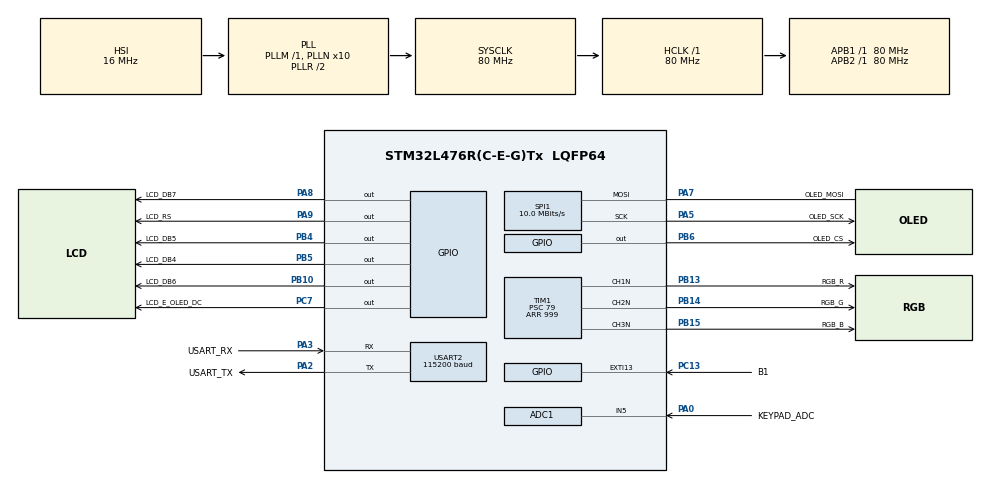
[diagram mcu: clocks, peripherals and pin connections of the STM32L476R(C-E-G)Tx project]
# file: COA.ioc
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ADC1.Channel-0\#ChannelRegularConversion=ADC_CHANNEL_5
ADC1.ClockPrescaler=ADC_CLOCK_ASYNC_DIV4
ADC1.NbrOfConversionFlag=1
ADC1.OffsetNumber-0\#ChannelRegularConversion=ADC_OFFSET_NONE
ADC1.Overrun=ADC_OVR_DATA_OVERWRITTEN
ADC1.Rank-0\#ChannelRegularConversion=1
ADC1.SamplingTime-0\#ChannelRegularConversion=ADC_SAMPLETIME_47CYCLES_5
ADC1.master=1
Mcu.Family=STM32L4
Mcu.Name=STM32L476R(C-E-G)Tx
Mcu.Package=LQFP64
NUCLEO-L476RG.BUTTON=1
NUCLEO-L476RG.LD2=false
NVIC.EXTI15_10_IRQn=true\:0\:0\:false\:false\:true\:false\:true\:true
NVIC.PriorityGroup=NVIC_PRIORITYGROUP_4
NVIC.TIM6_DAC_IRQn=true\:1\:0\:false\:false\:true\:true\:true\:true
PA0.GPIO_Label=KEYPAD_ADC
PA0.Mode=IN5-Single-Ended
PA0.Signal=ADC1_IN5
PA13\ (JTMS-SWDIO).GPIO_Label=TMS
PA13\ (JTMS-SWDIO).Signal=SYS_JTMS-SWDIO
PA14\ (JTCK-SWCLK).GPIO_Label=TCK
PA14\ (JTCK-SWCLK).Signal=SYS_JTCK-SWCLK
PA2.GPIO_Label=USART_TX
PA2.GPIO_Mode=GPIO_MODE_AF_PP
PA2.GPIO_PuPd=GPIO_NOPULL
PA2.GPIO_Speed=GPIO_SPEED_FREQ_VERY_HIGH
PA2.Mode=Asynchronous
PA2.Signal=USART2_TX
PA3.GPIO_Label=USART_RX
PA3.GPIO_Mode=GPIO_MODE_AF_PP
PA3.GPIO_PuPd=GPIO_NOPULL
PA3.GPIO_Speed=GPIO_SPEED_FREQ_VERY_HIGH
PA3.Mode=Asynchronous
PA3.Signal=USART2_RX
PA5.GPIO_Label=OLED_SCK
PA5.Mode=Simplex_Bidirectional_Master
PA5.Signal=SPI1_SCK
PA7.GPIO_Label=OLED_MOSI
PA7.Mode=Simplex_Bidirectional_Master
PA7.Signal=SPI1_MOSI
PA8.GPIO_Label=LCD_DB7
PA8.Signal=GPIO_Output
PA9.GPIO_Label=LCD_RS
PA9.Signal=GPIO_Output
PB10.GPIO_Label=LCD_DB6
PB10.Signal=GPIO_Output
PB13.GPIO_Label=RGB_R
PB13.Signal=S_TIM1_CH1N
PB14.GPIO_Label=RGB_G
PB14.Signal=S_TIM1_CH2N
PB15.GPIO_Label=RGB_B
PB15.Signal=S_TIM1_CH3N
PB3\ (JTDO-TRACESWO).GPIO_Label=SWO
PB3\ (JTDO-TRACESWO).Signal=SYS_JTDO-SWO
PB4\ (NJTRST).GPIO_Label=LCD_DB5
PB4\ (NJTRST).Signal=GPIO_Output
PB5.GPIO_Label=LCD_DB4
PB5.Signal=GPIO_Output
PB6.GPIO_Label=OLED_CS
PB6.PinState=GPIO_PIN_SET
PB6.Signal=GPIO_Output
PC13.GPIO_Label=B1
PC13.Signal=GPXTI13
PC14-OSC32_IN\ (PC14).Signal=RCC_OSC32_IN
PC15-OSC32_OUT\ (PC15).Signal=RCC_OSC32_OUT
PC7.GPIO_Label=LCD_E_OLED_DC
PC7.Signal=GPIO_Output
PH0-OSC_IN\ (PH0).Signal=RCC_OSC_IN
PH1-OSC_OUT\ (PH1).Signal=RCC_OSC_OUT
ProjectManager.HeapSize=0x200
ProjectManager.StackSize=0x400
ProjectManager.TargetToolchain=STM32CubeIDE
RCC.ADCFreq_Value=64000000
RCC.AHBFreq_Value=80000000
RCC.APB1Freq_Value=80000000
RCC.APB1TimFreq_Value=80000000
RCC.APB2Freq_Value=80000000
RCC.APB2TimFreq_Value=80000000
RCC.CortexFreq_Value=80000000
RCC.HCLKFreq_Value=80000000
RCC.HSE_VALUE=8000000
RCC.HSI_VALUE=16000000
RCC.LSE_VALUE=32768
RCC.MSI_VALUE=4000000
RCC.PLLN=10
RCC.PLLSourceVirtual=RCC_PLLSOURCE_HSI
RCC.PREFETCH_ENABLE=1
RCC.SYSCLKFreq_VALUE=80000000
RCC.SYSCLKSource=RCC_SYSCLKSOURCE_PLLCLK
RCC.USBFreq_Value=64000000
RCC.VCOOutputFreq_Value=160000000
SH.ADCx_IN5.0=ADC1_IN5,IN5-Single-Ended
SH.S_TIM1_CH1N.0=TIM1_CH1N,PWM Generation1 CH1N
SH.S_TIM1_CH2N.0=TIM1_CH2N,PWM Generation2 CH2N
SH.S_TIM1_CH3N.0=TIM1_CH3N,PWM Generation3 CH3N
SPI1.BaudRatePrescaler=SPI_BAUDRATEPRESCALER_8
SPI1.CalculateBaudRate=10.0 MBits/s
SPI1.DataSize=SPI_DATASIZE_8BIT
SPI1.Direction=SPI_DIRECTION_2LINES
SPI1.Mode=SPI_MODE_MASTER
SPI1.NSSPMode=SPI_NSS_PULSE_DISABLE
SPI1.VirtualType=VM_MASTER
TIM1.Channel-PWM\ Generation1\ CH1N=TIM_CHANNEL_1
TIM1.Channel-PWM\ Generation2\ CH2N=TIM_CHANNEL_2
TIM1.Channel-PWM\ Generation3\ CH3N=TIM_CHANNEL_3
TIM1.Period=999
TIM1.Prescaler=79
TIM6.Period=999
TIM6.Prescaler=79
USART2.BaudRate=115200
USART2.VirtualMode-Asynchronous=VM_ASYNC
VP_NUCLEO-L476RG_VS_BSP_COMMON.Mode=COMMON
VP_TIM1_VS_ClockSourceINT.Mode=Internal
VP_TIM6_VS_ClockSourceINT.Mode=Enable_Timer
board=NUCLEO-L476RG

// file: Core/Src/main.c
/* USER CODE BEGIN Header */
/**
  ******************************************************************************
  * @file           : main.c
  * @brief          : Main program body
  ******************************************************************************
  * @attention
  *
  * Copyright (c) 2026 STMicroelectronics.
  * All rights reserved.
  *
  * This software is licensed under terms that can be found in the LICENSE file
  * in the root directory of this software component.
  * If no LICENSE file comes with this software, it is provided AS-IS.
  *
  ******************************************************************************
  */
/* USER CODE END Header */
#include "main.h"

/* USER CODE BEGIN Includes */
#include "app.h"
#include <stdio.h>
/* USER CODE END Includes */

ADC_HandleTypeDef hadc1;

SPI_HandleTypeDef hspi1;

TIM_HandleTypeDef htim1;
TIM_HandleTypeDef htim6;

UART_HandleTypeDef huart2;

void SystemClock_Config(void);
static void MX_GPIO_Init(void);
static void MX_ADC1_Init(void);
static void MX_SPI1_Init(void);
static void MX_TIM1_Init(void);
static void MX_TIM6_Init(void);
static void MX_USART2_UART_Init(void);

int main(void)
{

  /* MCU Configuration--------------------------------------------------------*/

  /* Reset of all peripherals, Initializes the Flash interface and the Systick. */
  HAL_Init();

  /* Configure the system clock */
  SystemClock_Config();

  /* Initialize all configured peripherals */
  MX_GPIO_Init();
  MX_ADC1_Init();
  MX_SPI1_Init();
  MX_TIM1_Init();
  MX_TIM6_Init();
  MX_USART2_UART_Init();
  /* USER CODE BEGIN 2 */
  App_Init();      /* game init (also starts the TIM6 game tick) */
  /* USER CODE END 2 */

  /* Initialize USER push-button, will be used to trigger an interrupt each time it's pressed.*/
  BSP_PB_Init(BUTTON_USER, BUTTON_MODE_EXTI);

  /* Infinite loop */
  while (1)
  {

    /* USER CODE BEGIN 3 */
    App_Loop();
  }
  /* USER CODE END 3 */
}

void SystemClock_Config(void)
{
  RCC_OscInitTypeDef RCC_OscInitStruct = {0};
  RCC_ClkInitTypeDef RCC_ClkInitStruct = {0};

  /** Configure the main internal regulator output voltage
  */
  if (HAL_PWREx_ControlVoltageScaling(PWR_REGULATOR_VOLTAGE_SCALE1) != HAL_OK)
  {
    Error_Handler();
  }

  /** Initializes the RCC Oscillators according to the specified parameters
  * in the RCC_OscInitTypeDef structure.
  */
  RCC_OscInitStruct.OscillatorType = RCC_OSCILLATORTYPE_HSI;
  RCC_OscInitStruct.HSIState = RCC_HSI_ON;
  RCC_OscInitStruct.HSICalibrationValue = RCC_HSICALIBRATION_DEFAULT;
  RCC_OscInitStruct.PLL.PLLState = RCC_PLL_ON;
  RCC_OscInitStruct.PLL.PLLSource = RCC_PLLSOURCE_HSI;
  RCC_OscInitStruct.PLL.PLLM = 1;
  RCC_OscInitStruct.PLL.PLLN = 10;
  RCC_OscInitStruct.PLL.PLLP = RCC_PLLP_DIV7;
  RCC_OscInitStruct.PLL.PLLQ = RCC_PLLQ_DIV2;
  RCC_OscInitStruct.PLL.PLLR = RCC_PLLR_DIV2;
  if (HAL_RCC_OscConfig(&RCC_OscInitStruct) != HAL_OK)
  {
    Error_Handler();
  }

  /** Initializes the CPU, AHB and APB buses clocks
  */
  RCC_ClkInitStruct.ClockType = RCC_CLOCKTYPE_HCLK|RCC_CLOCKTYPE_SYSCLK
                              |RCC_CLOCKTYPE_PCLK1|RCC_CLOCKTYPE_PCLK2;
  RCC_ClkInitStruct.SYSCLKSource = RCC_SYSCLKSOURCE_PLLCLK;
  RCC_ClkInitStruct.AHBCLKDivider = RCC_SYSCLK_DIV1;
  RCC_ClkInitStruct.APB1CLKDivider = RCC_HCLK_DIV1;
  RCC_ClkInitStruct.APB2CLKDivider = RCC_HCLK_DIV1;

  if (HAL_RCC_ClockConfig(&RCC_ClkInitStruct, FLASH_LATENCY_4) != HAL_OK)
  {
    Error_Handler();
  }
}

static void MX_ADC1_Init(void)
{

  ADC_MultiModeTypeDef multimode = {0};
  ADC_ChannelConfTypeDef sConfig = {0};

  /** Common config
  */
  hadc1.Instance = ADC1;
  hadc1.Init.ClockPrescaler = ADC_CLOCK_ASYNC_DIV4;
  hadc1.Init.Resolution = ADC_RESOLUTION_12B;
  hadc1.Init.DataAlign = ADC_DATAALIGN_RIGHT;
  hadc1.Init.ScanConvMode = ADC_SCAN_DISABLE;
  hadc1.Init.EOCSelection = ADC_EOC_SINGLE_CONV;
  hadc1.Init.LowPowerAutoWait = DISABLE;
  hadc1.Init.ContinuousConvMode = DISABLE;
  hadc1.Init.NbrOfConversion = 1;
  hadc1.Init.DiscontinuousConvMode = DISABLE;
  hadc1.Init.ExternalTrigConv = ADC_SOFTWARE_START;
  hadc1.Init.ExternalTrigConvEdge = ADC_EXTERNALTRIGCONVEDGE_NONE;
  hadc1.Init.DMAContinuousRequests = DISABLE;
  hadc1.Init.Overrun = ADC_OVR_DATA_OVERWRITTEN;
  hadc1.Init.OversamplingMode = DISABLE;
  if (HAL_ADC_Init(&hadc1) != HAL_OK)
  {
    Error_Handler();
  }

  /** Configure the ADC multi-mode
  */
  multimode.Mode = ADC_MODE_INDEPENDENT;
  if (HAL_ADCEx_MultiModeConfigChannel(&hadc1, &multimode) != HAL_OK)
  {
    Error_Handler();
  }

  /** Configure Regular Channel
  */
  sConfig.Channel = ADC_CHANNEL_5;
  sConfig.Rank = ADC_REGULAR_RANK_1;
  sConfig.SamplingTime = ADC_SAMPLETIME_47CYCLES_5;
  sConfig.SingleDiff = ADC_SINGLE_ENDED;
  sConfig.OffsetNumber = ADC_OFFSET_NONE;
  sConfig.Offset = 0;
  if (HAL_ADC_ConfigChannel(&hadc1, &sConfig) != HAL_OK)
  {
    Error_Handler();
  }

}

static void MX_SPI1_Init(void)
{

  /* SPI1 parameter configuration*/
  hspi1.Instance = SPI1;
  hspi1.Init.Mode = SPI_MODE_MASTER;
  hspi1.Init.Direction = SPI_DIRECTION_2LINES;
  hspi1.Init.DataSize = SPI_DATASIZE_8BIT;
  hspi1.Init.CLKPolarity = SPI_POLARITY_LOW;
  hspi1.Init.CLKPhase = SPI_PHASE_1EDGE;
  hspi1.Init.NSS = SPI_NSS_SOFT;
  hspi1.Init.BaudRatePrescaler = SPI_BAUDRATEPRESCALER_8;
  hspi1.Init.FirstBit = SPI_FIRSTBIT_MSB;
  hspi1.Init.TIMode = SPI_TIMODE_DISABLE;
  hspi1.Init.CRCCalculation = SPI_CRCCALCULATION_DISABLE;
  hspi1.Init.CRCPolynomial = 7;
  hspi1.Init.CRCLength = SPI_CRC_LENGTH_DATASIZE;
  hspi1.Init.NSSPMode = SPI_NSS_PULSE_DISABLE;
  if (HAL_SPI_Init(&hspi1) != HAL_OK)
  {
    Error_Handler();
  }

}

static void MX_TIM1_Init(void)
{

  TIM_ClockConfigTypeDef sClockSourceConfig = {0};
  TIM_MasterConfigTypeDef sMasterConfig = {0};
  TIM_OC_InitTypeDef sConfigOC = {0};
  TIM_BreakDeadTimeConfigTypeDef sBreakDeadTimeConfig = {0};

  htim1.Instance = TIM1;
  htim1.Init.Prescaler = 79;
  htim1.Init.CounterMode = TIM_COUNTERMODE_UP;
  htim1.Init.Period = 999;
  htim1.Init.ClockDivision = TIM_CLOCKDIVISION_DIV1;
  htim1.Init.RepetitionCounter = 0;
  htim1.Init.AutoReloadPreload = TIM_AUTORELOAD_PRELOAD_DISABLE;
  if (HAL_TIM_Base_Init(&htim1) != HAL_OK)
  {
    Error_Handler();
  }
  sClockSourceConfig.ClockSource = TIM_CLOCKSOURCE_INTERNAL;
  if (HAL_TIM_ConfigClockSource(&htim1, &sClockSourceConfig) != HAL_OK)
  {
    Error_Handler();
  }
  if (HAL_TIM_PWM_Init(&htim1) != HAL_OK)
  {
    Error_Handler();
  }
  sMasterConfig.MasterOutputTrigger = TIM_TRGO_RESET;
  sMasterConfig.MasterOutputTrigger2 = TIM_TRGO2_RESET;
  sMasterConfig.MasterSlaveMode = TIM_MASTERSLAVEMODE_DISABLE;
  if (HAL_TIMEx_MasterConfigSynchronization(&htim1, &sMasterConfig) != HAL_OK)
  {
    Error_Handler();
  }
  sConfigOC.OCMode = TIM_OCMODE_PWM1;
  sConfigOC.Pulse = 0;
  sConfigOC.OCPolarity = TIM_OCPOLARITY_HIGH;
  sConfigOC.OCNPolarity = TIM_OCNPOLARITY_HIGH;
  sConfigOC.OCFastMode = TIM_OCFAST_DISABLE;
  sConfigOC.OCIdleState = TIM_OCIDLESTATE_RESET;
  sConfigOC.OCNIdleState = TIM_OCNIDLESTATE_RESET;
  if (HAL_TIM_PWM_ConfigChannel(&htim1, &sConfigOC, TIM_CHANNEL_1) != HAL_OK)
  {
    Error_Handler();
  }
  if (HAL_TIM_PWM_ConfigChannel(&htim1, &sConfigOC, TIM_CHANNEL_2) != HAL_OK)
  {
    Error_Handler();
  }
  if (HAL_TIM_PWM_ConfigChannel(&htim1, &sConfigOC, TIM_CHANNEL_3) != HAL_OK)
  {
    Error_Handler();
  }
  sBreakDeadTimeConfig.OffStateRunMode = TIM_OSSR_DISABLE;
  sBreakDeadTimeConfig.OffStateIDLEMode = TIM_OSSI_DISABLE;
  sBreakDeadTimeConfig.LockLevel = TIM_LOCKLEVEL_OFF;
  sBreakDeadTimeConfig.DeadTime = 0;
  sBreakDeadTimeConfig.BreakState = TIM_BREAK_DISABLE;
  sBreakDeadTimeConfig.BreakPolarity = TIM_BREAKPOLARITY_HIGH;
  sBreakDeadTimeConfig.BreakFilter = 0;
  sBreakDeadTimeConfig.Break2State = TIM_BREAK2_DISABLE;
  sBreakDeadTimeConfig.Break2Polarity = TIM_BREAK2POLARITY_HIGH;
  sBreakDeadTimeConfig.Break2Filter = 0;
  sBreakDeadTimeConfig.AutomaticOutput = TIM_AUTOMATICOUTPUT_DISABLE;
  if (HAL_TIMEx_ConfigBreakDeadTime(&htim1, &sBreakDeadTimeConfig) != HAL_OK)
  {
    Error_Handler();
  }
  HAL_TIM_MspPostInit(&htim1);

}

static void MX_TIM6_Init(void)
{

  TIM_MasterConfigTypeDef sMasterConfig = {0};

  htim6.Instance = TIM6;
  htim6.Init.Prescaler = 79;
  htim6.Init.CounterMode = TIM_COUNTERMODE_UP;
  htim6.Init.Period = 999;
  htim6.Init.AutoReloadPreload = TIM_AUTORELOAD_PRELOAD_DISABLE;
  if (HAL_TIM_Base_Init(&htim6) != HAL_OK)
  {
    Error_Handler();
  }
  sMasterConfig.MasterOutputTrigger = TIM_TRGO_RESET;
  sMasterConfig.MasterSlaveMode = TIM_MASTERSLAVEMODE_DISABLE;
  if (HAL_TIMEx_MasterConfigSynchronization(&htim6, &sMasterConfig) != HAL_OK)
  {
    Error_Handler();
  }

}

static void MX_USART2_UART_Init(void)
{

  huart2.Instance = USART2;
  huart2.Init.BaudRate = 115200;
  huart2.Init.WordLength = UART_WORDLENGTH_8B;
  huart2.Init.StopBits = UART_STOPBITS_1;
  huart2.Init.Parity = UART_PARITY_NONE;
  huart2.Init.Mode = UART_MODE_TX_RX;
  huart2.Init.HwFlowCtl = UART_HWCONTROL_NONE;
  huart2.Init.OverSampling = UART_OVERSAMPLING_16;
  huart2.Init.OneBitSampling = UART_ONE_BIT_SAMPLE_DISABLE;
  huart2.AdvancedInit.AdvFeatureInit = UART_ADVFEATURE_NO_INIT;
  if (HAL_UART_Init(&huart2) != HAL_OK)
  {
    Error_Handler();
  }

}

static void MX_GPIO_Init(void)
{
  GPIO_InitTypeDef GPIO_InitStruct = {0};

  /* GPIO Ports Clock Enable */
  __HAL_RCC_GPIOC_CLK_ENABLE();
  __HAL_RCC_GPIOH_CLK_ENABLE();
  __HAL_RCC_GPIOA_CLK_ENABLE();
  __HAL_RCC_GPIOB_CLK_ENABLE();

  /*Configure GPIO pin Output Level */
  HAL_GPIO_WritePin(GPIOB, LCD_DB6_Pin|LCD_DB5_Pin|LCD_DB4_Pin, GPIO_PIN_RESET);

  /*Configure GPIO pin Output Level */
  HAL_GPIO_WritePin(OLED_CS_GPIO_Port, OLED_CS_Pin, GPIO_PIN_SET);

  /*Configure GPIO pin Output Level */
  HAL_GPIO_WritePin(LCD_E_OLED_DC_GPIO_Port, LCD_E_OLED_DC_Pin, GPIO_PIN_RESET);

  /*Configure GPIO pin Output Level */
  HAL_GPIO_WritePin(GPIOA, LCD_DB7_Pin|LCD_RS_Pin, GPIO_PIN_RESET);

  /*Configure GPIO pins : LCD_DB6_Pin LCD_DB5_Pin LCD_DB4_Pin OLED_CS_Pin */
  GPIO_InitStruct.Pin = LCD_DB6_Pin|LCD_DB5_Pin|LCD_DB4_Pin|OLED_CS_Pin;
  GPIO_InitStruct.Mode = GPIO_MODE_OUTPUT_PP;
  GPIO_InitStruct.Pull = GPIO_NOPULL;
  GPIO_InitStruct.Speed = GPIO_SPEED_FREQ_LOW;
  HAL_GPIO_Init(GPIOB, &GPIO_InitStruct);

  /*Configure GPIO pin : LCD_E_OLED_DC_Pin */
  GPIO_InitStruct.Pin = LCD_E_OLED_DC_Pin;
  GPIO_InitStruct.Mode = GPIO_MODE_OUTPUT_PP;
  GPIO_InitStruct.Pull = GPIO_NOPULL;
  GPIO_InitStruct.Speed = GPIO_SPEED_FREQ_LOW;
  HAL_GPIO_Init(LCD_E_OLED_DC_GPIO_Port, &GPIO_InitStruct);

  /*Configure GPIO pins : LCD_DB7_Pin LCD_RS_Pin */
  GPIO_InitStruct.Pin = LCD_DB7_Pin|LCD_RS_Pin;
  GPIO_InitStruct.Mode = GPIO_MODE_OUTPUT_PP;
  GPIO_InitStruct.Pull = GPIO_NOPULL;
  GPIO_InitStruct.Speed = GPIO_SPEED_FREQ_LOW;
  HAL_GPIO_Init(GPIOA, &GPIO_InitStruct);

}

/* USER CODE BEGIN 4 */

/* printf() -> USART2 (ST-LINK virtual COM port, 115200 8N1) */
int __io_putchar(int ch)
{
  uint8_t c = (uint8_t)ch;
  HAL_UART_Transmit(&huart2, &c, 1, 10);
  return ch;
}

/* The interrupt callbacks (TIM6 game tick, EXTI blue button) are in app.c */

/* USER CODE END 4 */

void Error_Handler(void)
{
  __disable_irq();
  while (1)
  {
  }
}
